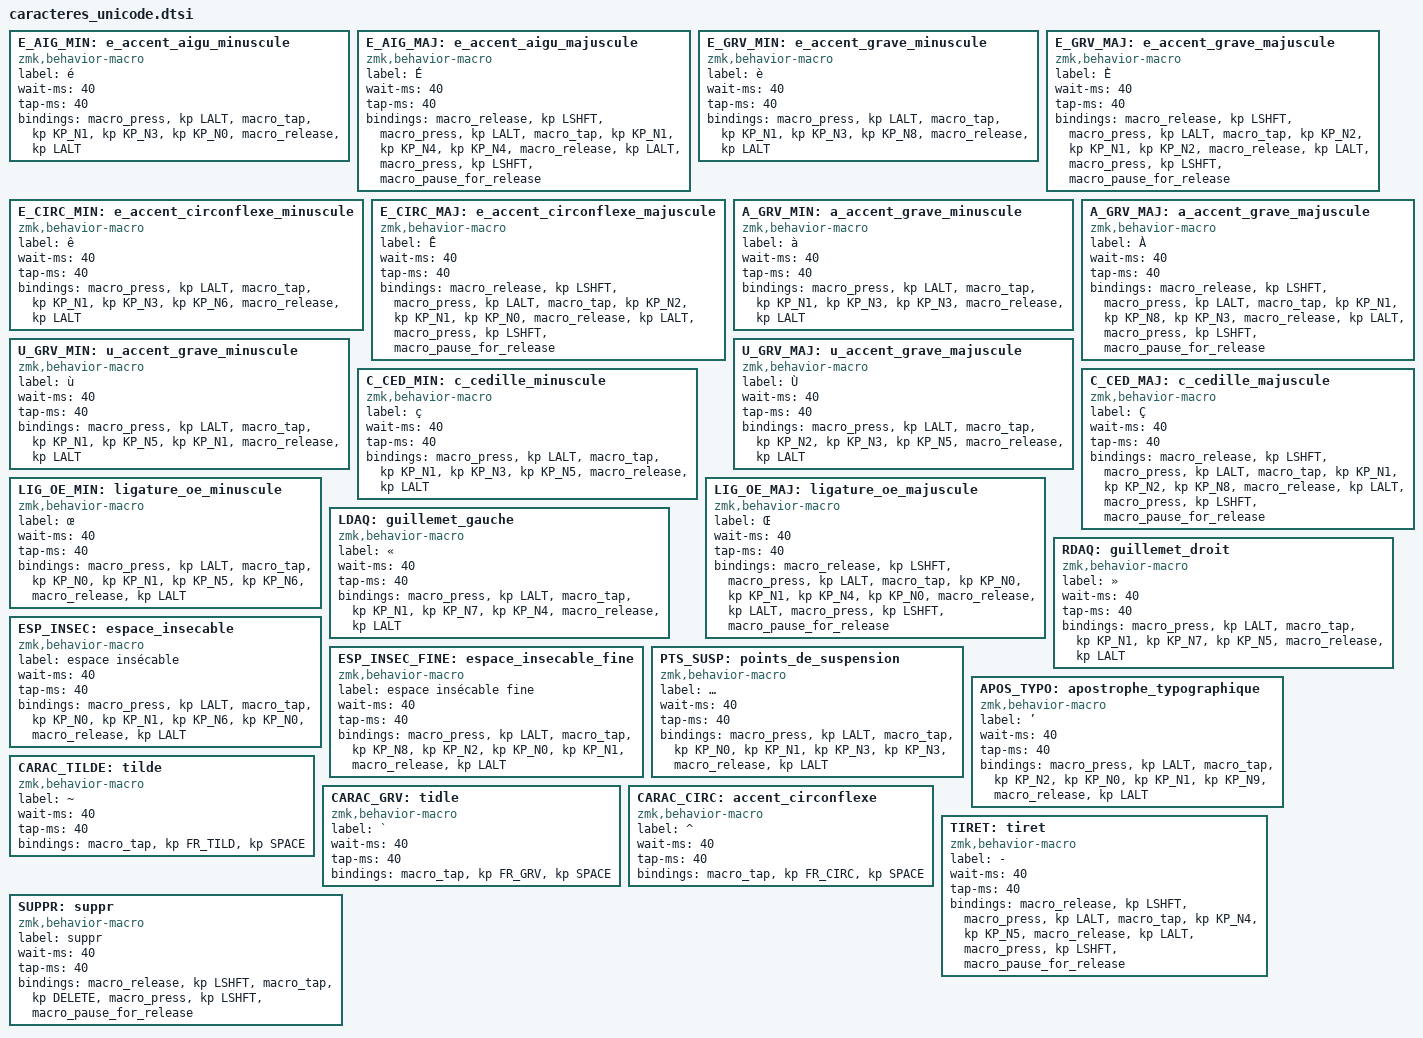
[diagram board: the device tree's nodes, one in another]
E_AIG_MIN: e_accent_aigu_minuscule {
	compatible = "zmk,behavior-macro";
	label = "é";
	#binding-cells = <0>;
	wait-ms = <40>;
	tap-ms = <40>;
	bindings = <&macro_press   	 &kp LALT>
			 , <&macro_tap     	 &kp KP_N1 &kp KP_N3 &kp KP_N0>
			 , <&macro_release 	 &kp LALT>
	;
};

E_AIG_MAJ: e_accent_aigu_majuscule {
	compatible = "zmk,behavior-macro";
	label = "É";
	#binding-cells = <0>;
	wait-ms = <40>;
	tap-ms = <40>;
	bindings = <&macro_release   &kp LSHFT>
			 	, <&macro_press   	 &kp LALT>
			 	, <&macro_tap     	 &kp KP_N1 &kp KP_N4 &kp KP_N4>
			 	, <&macro_release 	 &kp LALT>
        	 , <&macro_press     &kp LSHFT>
        	 , <&macro_pause_for_release>
	;
};




E_GRV_MIN: e_accent_grave_minuscule {
	compatible = "zmk,behavior-macro";
	label = "è";
	#binding-cells = <0>;
	wait-ms = <40>;
	tap-ms = <40>;
	bindings = <&macro_press   	 &kp LALT>
			 , <&macro_tap     	 &kp KP_N1 &kp KP_N3 &kp KP_N8>
			 , <&macro_release 	 &kp LALT>
	;
};

E_GRV_MAJ: e_accent_grave_majuscule {
	compatible = "zmk,behavior-macro";
	label = "È";
	#binding-cells = <0>;
	wait-ms = <40>;
	tap-ms = <40>;
	bindings = <&macro_release   &kp LSHFT>
			 	, <&macro_press   	 &kp LALT>
			 	, <&macro_tap     	 &kp KP_N2 &kp KP_N1 &kp KP_N2>
			 	, <&macro_release 	 &kp LALT>
        	 , <&macro_press     &kp LSHFT>
        	 , <&macro_pause_for_release>
	;
};



E_CIRC_MIN: e_accent_circonflexe_minuscule {
	compatible = "zmk,behavior-macro";
	label = "ê";
	#binding-cells = <0>;
	wait-ms = <40>;
	tap-ms = <40>;
	bindings = <&macro_press   	 &kp LALT>
			 , <&macro_tap     	 &kp KP_N1 &kp KP_N3 &kp KP_N6>
			 , <&macro_release 	 &kp LALT>
	;
};

E_CIRC_MAJ: e_accent_circonflexe_majuscule {
	compatible = "zmk,behavior-macro";
	label = "Ê";
	#binding-cells = <0>;
	wait-ms = <40>;
	tap-ms = <40>;
	bindings = <&macro_release   &kp LSHFT>
			 	, <&macro_press   	 &kp LALT>
			 	, <&macro_tap     	 &kp KP_N2 &kp KP_N1 &kp KP_N0>
			 	, <&macro_release 	 &kp LALT>
        	 , <&macro_press     &kp LSHFT>
        	 , <&macro_pause_for_release>
	;
};



A_GRV_MIN: a_accent_grave_minuscule {
	compatible = "zmk,behavior-macro";
	label = "à";
	#binding-cells = <0>;
	wait-ms = <40>;
	tap-ms = <40>;
	bindings = <&macro_press   	 &kp LALT>
			 , <&macro_tap     	 &kp KP_N1 &kp KP_N3 &kp KP_N3>
			 , <&macro_release 	 &kp LALT>
	;
};

A_GRV_MAJ: a_accent_grave_majuscule {
	compatible = "zmk,behavior-macro";
	label = "À";
	#binding-cells = <0>;
	wait-ms = <40>;
	tap-ms = <40>;
	bindings = <&macro_release   &kp LSHFT>
			 	, <&macro_press   	 &kp LALT>
			 	, <&macro_tap     	 &kp KP_N1 &kp KP_N8 &kp KP_N3>
			 	, <&macro_release 	 &kp LALT>
        	 , <&macro_press     &kp LSHFT>
        	 , <&macro_pause_for_release>
	;
};



U_GRV_MIN: u_accent_grave_minuscule {
	compatible = "zmk,behavior-macro";
	label = "ù";
	#binding-cells = <0>;
	wait-ms = <40>;
	tap-ms = <40>;
	bindings = <&macro_press   	 &kp LALT>
			 , <&macro_tap     	 &kp KP_N1 &kp KP_N5 &kp KP_N1>
			 , <&macro_release 	 &kp LALT>
	;
};

U_GRV_MAJ: u_accent_grave_majuscule {
	compatible = "zmk,behavior-macro";
	label = "Ù";
	#binding-cells = <0>;
	wait-ms = <40>;
	tap-ms = <40>;
	bindings = <&macro_press   	 &kp LALT>
			 , <&macro_tap     	 &kp KP_N2 &kp KP_N3 &kp KP_N5>
			 , <&macro_release 	 &kp LALT>
	;
};



C_CED_MIN: c_cedille_minuscule {
	compatible = "zmk,behavior-macro";
	label = "ç";
	#binding-cells = <0>;
	wait-ms = <40>;
	tap-ms = <40>;
	bindings = <&macro_press   	 &kp LALT>
			 , <&macro_tap     	 &kp KP_N1 &kp KP_N3 &kp KP_N5>
			 , <&macro_release 	 &kp LALT>
	;
};

C_CED_MAJ: c_cedille_majuscule {
	compatible = "zmk,behavior-macro";
	label = "Ç";
	#binding-cells = <0>;
	wait-ms = <40>;
	tap-ms = <40>;
	bindings = <&macro_release   &kp LSHFT>
			 	, <&macro_press   	 &kp LALT>
			 	, <&macro_tap     	 &kp KP_N1 &kp KP_N2 &kp KP_N8>
			 	, <&macro_release 	 &kp LALT>
        	 , <&macro_press     &kp LSHFT>
        	 , <&macro_pause_for_release>
	;
};



LIG_OE_MIN: ligature_oe_minuscule {
	compatible = "zmk,behavior-macro";
	label = "œ";
	#binding-cells = <0>;
	wait-ms = <40>;
	tap-ms = <40>;
	bindings = <&macro_press   	 &kp LALT>
			 , <&macro_tap     	 &kp KP_N0 &kp KP_N1 &kp KP_N5 &kp KP_N6>
			 , <&macro_release 	 &kp LALT>
	;
};

LIG_OE_MAJ: ligature_oe_majuscule {
	compatible = "zmk,behavior-macro";
	label = "Œ";
	#binding-cells = <0>;
	wait-ms = <40>;
	tap-ms = <40>;
	bindings = <&macro_release   &kp LSHFT>
			 	, <&macro_press   	 &kp LALT>
			 	, <&macro_tap     	 &kp KP_N0 &kp KP_N1 &kp KP_N4 &kp KP_N0>
			 	, <&macro_release 	 &kp LALT>
        	 , <&macro_press     &kp LSHFT>
        	 , <&macro_pause_for_release>
	;
};



LDAQ: guillemet_gauche {
	compatible = "zmk,behavior-macro";
	label = "«";
	#binding-cells = <0>;
	wait-ms = <40>;
	tap-ms = <40>;
	bindings = <&macro_press   	 &kp LALT>
			 , <&macro_tap     	 &kp KP_N1 &kp KP_N7 &kp KP_N4>
			 , <&macro_release 	 &kp LALT>
	;
};

RDAQ: guillemet_droit {
	compatible = "zmk,behavior-macro";
	label = "»";
	#binding-cells = <0>;
	wait-ms = <40>;
	tap-ms = <40>;
	bindings = <&macro_press   	 &kp LALT>
			 , <&macro_tap     	 &kp KP_N1 &kp KP_N7 &kp KP_N5>
			 , <&macro_release 	 &kp LALT>
	;
};



ESP_INSEC: espace_insecable {
	compatible = "zmk,behavior-macro";
	label = "espace insécable";
	#binding-cells = <0>;
	wait-ms = <40>;
	tap-ms = <40>;
	bindings = <&macro_press   	 &kp LALT>
			 , <&macro_tap     	 &kp KP_N0 &kp KP_N1 &kp KP_N6 &kp KP_N0>
			 , <&macro_release 	 &kp LALT>
	;
};

ESP_INSEC_FINE: espace_insecable_fine {
	compatible = "zmk,behavior-macro";
	label = "espace insécable fine";
	#binding-cells = <0>;
	wait-ms = <40>;
	tap-ms = <40>;
	bindings = <&macro_press   	 &kp LALT>
			 , <&macro_tap     	 &kp KP_N8 &kp KP_N2 &kp KP_N0 &kp KP_N1>
			 , <&macro_release 	 &kp LALT>
	;
};



PTS_SUSP: points_de_suspension {
	compatible = "zmk,behavior-macro";
	label = "…";
	#binding-cells = <0>;
	wait-ms = <40>;
	tap-ms = <40>;
	bindings = <&macro_press   	 &kp LALT>
			 , <&macro_tap     	 &kp KP_N0 &kp KP_N1 &kp KP_N3 &kp KP_N3>
			 , <&macro_release 	 &kp LALT>
	;
};

APOS_TYPO: apostrophe_typographique {
	compatible = "zmk,behavior-macro";
	label = "’";
	#binding-cells = <0>;
	wait-ms = <40>;
	tap-ms = <40>;
	bindings = <&macro_press   	 &kp LALT>
			 , <&macro_tap     	 &kp KP_N2 &kp KP_N0 &kp KP_N1 &kp KP_N9>
			 , <&macro_release 	 &kp LALT>
	;
};



CARAC_TILDE: tilde {
	compatible = "zmk,behavior-macro";
	label = "~";
	#binding-cells = <0>;
	wait-ms = <40>;
	tap-ms = <40>;
	bindings = <&macro_tap     	 &kp FR_TILD &kp SPACE>
	;
};

CARAC_GRV: tidle {
	compatible = "zmk,behavior-macro";
	label = "`";
	#binding-cells = <0>;
	wait-ms = <40>;
	tap-ms = <40>;
	bindings = <&macro_tap     	 &kp FR_GRV &kp SPACE>
	;
};

CARAC_CIRC: accent_circonflexe {
	compatible = "zmk,behavior-macro";
	label = "^";
	#binding-cells = <0>;
	wait-ms = <40>;
	tap-ms = <40>;
	bindings = <&macro_tap     	 &kp FR_CIRC &kp SPACE>
	;
};



TIRET: tiret {
	compatible = "zmk,behavior-macro";
	label = "-";
	#binding-cells = <0>;
	wait-ms = <40>;
	tap-ms = <40>;
	bindings = <&macro_release   &kp LSHFT>
			 	, <&macro_press   	 &kp LALT>
			 	, <&macro_tap     	 &kp KP_N4 &kp KP_N5>
			 	, <&macro_release 	 &kp LALT>
        	 , <&macro_press     &kp LSHFT>
        	 , <&macro_pause_for_release>
	;
};

SUPPR: suppr {
	compatible = "zmk,behavior-macro";
	label = "suppr";
	#binding-cells = <0>;
	wait-ms = <40>;
	tap-ms = <40>;
	bindings = <&macro_release   &kp LSHFT>
			 	, <&macro_tap     	 &kp DELETE>
        	 , <&macro_press     &kp LSHFT>
        	 , <&macro_pause_for_release>
	;
};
